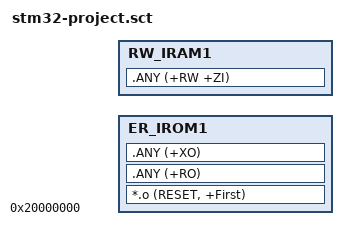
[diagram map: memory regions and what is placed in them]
; *************************************************************
; *** Scatter-Loading Description File generated by uVision ***
; *************************************************************

 ; load region size_region
LR_IROM1 0x08000000 0x00040000  
{
	; RO/EO data
	ER_IROM1 0x20000000 
	{
		*.o (RESET, +First)
		.ANY (+RO)
		.ANY (+XO)
	}
	; RW data
	RW_IRAM1 +0 
	{  
		.ANY (+RW +ZI)
	}
}

